AUTOSAR XML (schema 4-3-0)
package /ARRoot
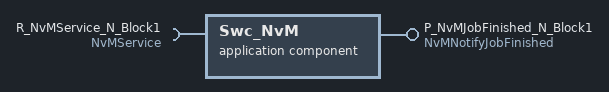
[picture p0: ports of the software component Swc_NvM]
  application sw component type Swc_NvM
    provide port P_NvMJobFinished_N_Block1: server-com-spec{operation=JobFinished, queue-length=1}, provided-interface=NvMNotifyJobFinished
    require port R_NvMService_N_Block1: client-com-spec=GetErrorStatus, required-interface=NvMService
    behavior InternalBehavior
